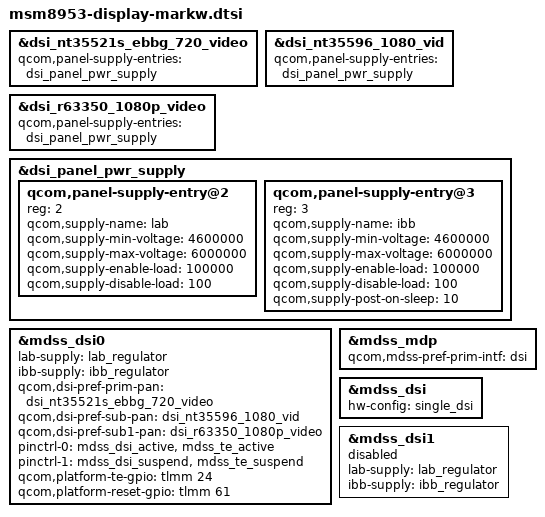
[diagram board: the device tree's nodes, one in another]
/*
 * Copyright (c) 2017, The Linux Foundation. All rights reserved.
 *
 * This program is free software; you can redistribute it and/or modify
 * it under the terms of the GNU General Public License version 2 and
 * only version 2 as published by the Free Software Foundation.
 *
 * This program is distributed in the hope that it will be useful,
 * but WITHOUT ANY WARRANTY; without even the implied warranty of
 * MERCHANTABILITY or FITNESS FOR A PARTICULAR PURPOSE.  See the
 * GNU General Public License for more details.
 */

#include "panels/dsi-panel-nt35521s-ebbg-720p-video.dtsi"
#include "panels/dsi-panel-nt35596-ebbg-1080p-video.dtsi"
#include "panels/dsi-panel-r63350-tianma-1080p-video.dtsi"


&dsi_nt35521s_ebbg_720_video {
	qcom,panel-supply-entries = <&dsi_panel_pwr_supply>;
};

&dsi_nt35596_1080_vid {
	qcom,panel-supply-entries = <&dsi_panel_pwr_supply>;
};

&dsi_r63350_1080p_video {
	qcom,panel-supply-entries = <&dsi_panel_pwr_supply>;
};

&dsi_panel_pwr_supply {
	qcom,panel-supply-entry@2 {
		reg = <2>;
		qcom,supply-name = "lab";
		qcom,supply-min-voltage = <4600000>;
		qcom,supply-max-voltage = <6000000>;
		qcom,supply-enable-load = <100000>;
		qcom,supply-disable-load = <100>;
	};

	qcom,panel-supply-entry@3 {
		reg = <3>;
		qcom,supply-name = "ibb";
		qcom,supply-min-voltage = <4600000>;
		qcom,supply-max-voltage = <6000000>;
		qcom,supply-enable-load = <100000>;
		qcom,supply-disable-load = <100>;
		qcom,supply-post-on-sleep = <10>;
	};
};

&mdss_dsi0 {
        lab-supply = <&lab_regulator>;
        ibb-supply = <&ibb_regulator>;
/*        /delete-property/ vdd-supply; */
        qcom,dsi-pref-prim-pan = <&dsi_nt35521s_ebbg_720_video>;
        qcom,dsi-pref-sub-pan = <&dsi_nt35596_1080_vid>;
        qcom,dsi-pref-sub1-pan = <&dsi_r63350_1080p_video>;
        pinctrl-names = "mdss_default", "mdss_sleep";
        pinctrl-0 = <&mdss_dsi_active &mdss_te_active>;
        pinctrl-1 = <&mdss_dsi_suspend &mdss_te_suspend>;
        qcom,platform-te-gpio = <&tlmm 24 0>;
        qcom,platform-reset-gpio = <&tlmm 61 0>;
};

&mdss_mdp {
	qcom,mdss-pref-prim-intf = "dsi";
};

&mdss_dsi {
	hw-config = "single_dsi";
};

&mdss_dsi1 {
	status = "disabled";
	lab-supply = <&lab_regulator>;
	ibb-supply = <&ibb_regulator>;
};
